# DSI_Protocol_Engine register map
Vendor: Texas Instruments
Registers are 32-bit, read-write, reset 0x0 unless marked. A register's access mark holds for its fields unless they carry their own. Offsets are as the file gives them; [hi:lo] are bit positions; {n}, {i} and the like mark numbered series; 'fields as' and 'values as' point back to an identical list.

## DSI_Protocol_Engine (part 2 of 2)
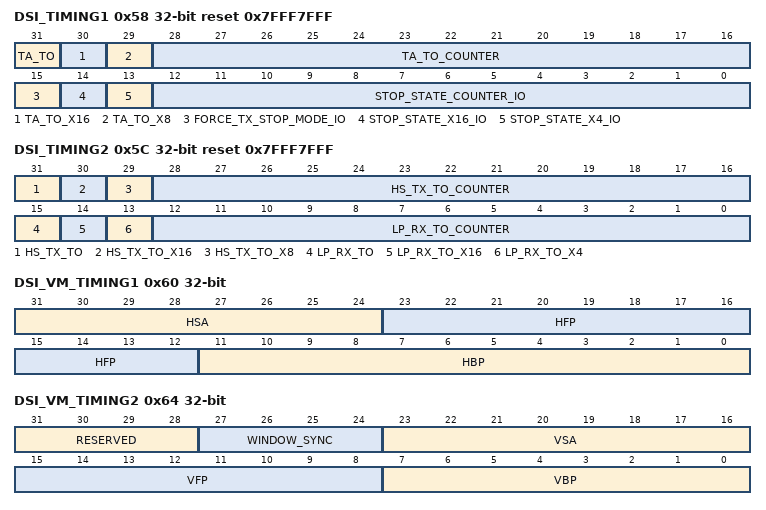
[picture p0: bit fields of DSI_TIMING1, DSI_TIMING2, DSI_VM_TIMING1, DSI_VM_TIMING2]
0x58 DSI_TIMING1 reset 0x7FFF7FFF — TIMING1 REGISTER This register controls the DSI Protocol Engine module timers. Any bit field can be modified while.IF_EN is set to 1. It is used to indicate the number of DSI_FCLK clock cycles for the timers FORCE_TX_STOP_TIMER and TA_TO_TIMER
  [31] TA_TO — Enables the turn-around timer
    0=Turn-around counter is disabled; 1=Turn-around counter is enabled (required to receive TA interrupt in case the turn-around procedure is not successful)
  [30] TA_TO_X16 — Multiplication factor for the number of DSI_FCLK clock cycles defined in TA_TO_COUNTER bit field
    0=The number of DSI_FCLK clock cycles defined in TA_TO_COUNTER is multiplied by 1x; 1=The number of DSI_FCLK clock cycles defined in TA_TO_COUNTER is multiplied by 16x
  [29] TA_TO_X8 — Multiplication factor for the number of DSI_FCLK clock cycles defined in TA_TO_COUNTER bit field
    0=The number of DSI_FCLK clock cycles defined in TA_TO_COUNTER is multiplied by 1x; 1=The number of DSI_FCLK clock cycles defined in TA_TO_COUNTER is multiplied by 8x
  [28:16] TA_TO_COUNTER — Turn around counter. It indicates the number of DSI_FCLK clock cycles to wait for the change of the Direction PPI signal according to the TurnRequest signalThe value is from 0 to 8191.
  [15] FORCE_TX_STOP_MODE_IO — Control of ForceTxStopMode signal
    0=Deassertion of ForceTxStopMode. The hardware reset the bit at the end of the ForceTXStopMode assertion. The SW can reset the bit to stop the assertion of the ForceTXStopMode signal prior to the completion of the period.; 1=Assertion of ForceTxStopMode
  [14] STOP_STATE_X16_IO — Multiplication factor for the number of DSI_FCLK clock cycles defined in STOP_STATE_COUNTER_IO bit field
    0=The number of DSI_FCLK clock cycles defined in STOP_STATE _COUNTER_IO is multiplied by 1x; 1=The number of DSI_FCLK clock cycles defined in STOP_STATE _COUNTER_IO is multiplied by 16x
  [13] STOP_STATE_X4_IO — Multiplication factor for the number of DSI_FCLK clock cycles defined in STOP_STATE_COUNTER_IO bit field
    0=The number of DSI_FCLK clock cycles defined in STOP_STATE _COUNTER_IO is multiplied by 1x; 1=The number of DSI_FCLK clock cycles defined in STOP_STATE _COUNTER_IO is multiplied by 4x
  [12:0] STOP_STATE_COUNTER_IO — Stop state counter. It indicates the number of DSI_FCLK clock cycles to assert ForceTXStopMode signal. The value is from 0 to 8191.
0x5C DSI_TIMING2 reset 0x7FFF7FFF — TIMING2 REGISTER This register controls the DSI Protocol Engine module timers. Any bit field can be modified while.IF_EN is set to 1. It is used to indicate the number of TxByteClkHS clock cycles for the timers HS_TX_TIMER and LP_RX_TIMER
  [31] HS_TX_TO — Enables the HS TX timer.
    values as DSI_TIMING1.TA_TO
  [30] HS_TX_TO_X16 — Multiplication factor for the number of TxByteClkHS functional clock cycles defined in HS_TX_COUNTER bit field
    0=The number of TxByteClkHS functional clock cycles defined in HS_TX_TO_COUNTER is multiplied by 1x; 1=The number of TxByteClkHS functional clock cycles defined in HS_TX_TO_COUNTER is multiplied by 16x
  [29] HS_TX_TO_X8 — Multiplication factor for the number of TxByteClkHS functional clock cycles defined in HS_TX_COUNTER bit
    0=The number of TxByteClkHS functional clock cycles defined in HS_TX_TO_COUNTER is multiplied by 1x; 1=The number of TxByteClkHS functional clock cycles defined in HS_TX_TO_COUNTER is multiplied by 8x
  [28:16] HS_TX_TO_COUNTER — HS_TX_TIMER counter. It indicates the number of TxByteClkHS function clock cycles for the HS TX timer.The value is from 0 to 8191.
  [15] LP_RX_TO — Enables the LP RX timer.
    values as DSI_TIMING1.TA_TO
  [14] LP_RX_TO_X16 — Multiplication factor for the number of DSI_FCLK clock cycles defined in LP_RX_COUNTER bit field
    0=The number of DSI_FCLK clock cycles defined in LP_RX_TO_COUNTER is multiplied by 1x; 1=The number of DSI_FCLK clock cycles defined in LP_RX_TO_COUNTER is multiplied by 16x
  [13] LP_RX_TO_X4 — Multiplication factor for the number of DSI_FCLK clock cycles defined in LP_RX_COUNTER bit
    0=The number of DSI_FCLK clock cycles defined in LP_RX_TO_COUNTER is multiplied by 1x; 1=The number of DSI_FCLK clock cycles defined in LP_RX_TO_COUNTER is multiplied by 4x
  [12:0] LP_RX_TO_COUNTER — LP_RX_TIMER counter. It indicates the number of DSI_FCLK clock cycles for the LP RX timer.The value is from 0 to 8191.
0x60 DSI_VM_TIMING1 — VIDEO MODE TIMING REGISTER This register defines the video mode timing.
  [31:24] HSA — Defines the horizontal Sync active period used in video mode in number of byte clock cycles (TxByteClkHS)The supported values are from 0 to 255.
  [23:12] HFP — Defines the horizontal front porch used in video mode in number of byte clock cycles (TxByteClkHS)The supported values are from 0 to 255
  [11:0] HBP — Defines the horizontal back porch used in video mode in number of byte clock cycles (TxByteClkHS)The supported values are from 0 to 255
0x64 DSI_VM_TIMING2 — VIDEO MODE TIMING REGISTER This register defines the video mode timing.
  [31:28] RESERVED — Write 0s for future compatibility.Reads returns 0.
  [27:24] WINDOW_SYNC — Number of TxByteClkHS clock cycles for the synchronization window. An interrupt for synchronization lost is generated when the received synchronization on video port is not inside the window. The DSI protocol engine does not change its own timings if the synch is inside the window. The valid values are from 0 to 15.
  [23:16] VSA — Defines the vertical Sync active period used in video mode in number of lines.The supported values are from 0 to 255 It is used to generate the short packet for End of Vertical synchronization.
  [15:8] VFP — Defines the vertical front porch used in video mode in number of lines.The supported values are from 0 to 255
  [7:0] VBP — Defines the vertical back porch used in video mode in number of lines.The supported values are from 0 to 255
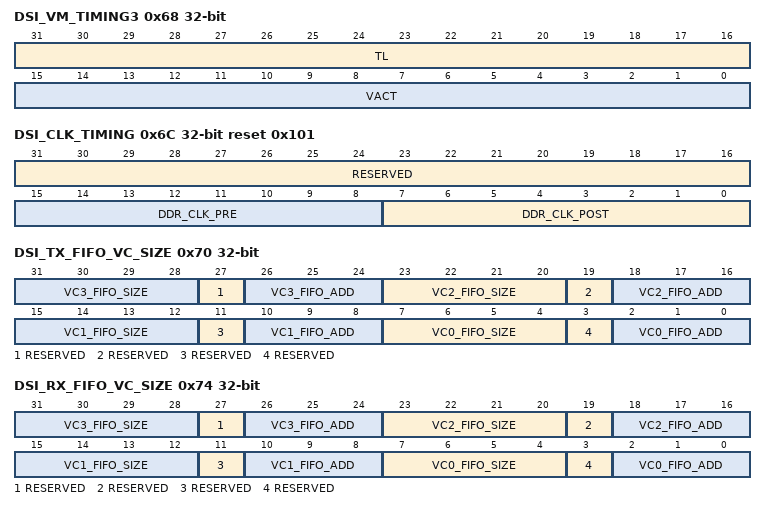
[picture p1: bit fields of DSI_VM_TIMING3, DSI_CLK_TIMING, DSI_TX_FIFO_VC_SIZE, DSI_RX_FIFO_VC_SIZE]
0x68 DSI_VM_TIMING3 — VIDEO MODE TIMING REGISTER This register defines the video mode timing.
  [31:16] TL — Defines the number of length of the line in video mode in number of byte clock cycles (TxByteClkHS)The supported values are from 0 to 8192. The values from 8193 to 65535 are not supported.
  [15:0] VACT — Defines the number of active lines used in video mode.The supported values are from 0 to 65535
0x6C DSI_CLK_TIMING reset 0x101 — CLOCK TIMING REGISTER This register controls the DSI Protocol Engine module timers. This register should not be modified while.IF_EN is set to 1.
  [31:16] RESERVED — Write 0s for future compatibility.Reads returns 0.
  [15:8] DDR_CLK_PRE — Indicates the number of TxByteClkHS cycles between the start of the DDR clock and the assertion of the data request signal. The values from 1 to 255 are valid. The value 0 is reserved. The value is not used ifDSI_CLK_CTRL[13] DDR_CLK_ALWAYS_ON is set to 1 since the DDR clock is always present.
  [7:0] DDR_CLK_POST — Indicates the number of TxByteClkHS cycles after the deassertion of the data request signal and the stop of the DDR clock. The values from 1 to 255 are valid. The value 0 is reserved. The value is not used ifDSI_CLK_CTRL[13] DDR_CLK_ALWAYS_ON is set to 1 since the DDR clock is always present.
0x70 DSI_TX_FIFO_VC_SIZE — Defines the corresponding memory entries allocated for each VC. The VC must be disabled to allocate/un-allocate some entries in the TX FIFO.
  [8n+7:8n+4] VC{n}_FIFO_SIZE (n=0..3) — Size of the FIFO allocated for VC {n}. For a complete description, refer to.
  [27] RESERVED — Write 0s for future compatibility.Reads returns 0.
  [26:24] VC3_FIFO_ADD — Address of the space allocated in the FIFO for VC 3. For a complete description, refer to.
  [19] RESERVED — Write 0s for future compatibility.Reads returns 0.
  [18:16] VC2_FIFO_ADD — Address of the space allocated in the FIFO for VC 2. For a complete description, refer to.
  [11] RESERVED — Write 0s for future compatibility.Reads returns 0.
  [10:8] VC1_FIFO_ADD — Address of the space allocated in the FIFO for VC 1.For a complete description, refer to.
  [3] RESERVED — Write 0s for future compatibility.Reads returns 0.
  [2:0] VC0_FIFO_ADD — Address of the space allocated in the FIFO for VC 0. For a complete description, refer to.
0x74 DSI_RX_FIFO_VC_SIZE — Defines the corresponding memory entries allocated for each VC and the addresses. The VC must be disabled to allocate/un-allocate some entries in the RX FIFO.
  [8n+7:8n+4] VC{n}_FIFO_SIZE (n=0..3) — Size of the FIFO allocated for VC {n}. For a complete description, refer to.
  [27] RESERVED — Write 0s for future compatibility.Reads returns 0.
  [26:24] VC3_FIFO_ADD — Address of the space allocated in the FIFO for VC 3.For a complete description, refer to.
  [19] RESERVED — Write 0s for future compatibility.Reads returns 0.
  [18:16] VC2_FIFO_ADD — Address of the space allocated in the FIFO for VC 2. For a complete description, refer to.
  [11] RESERVED — Write 0s for future compatibility.Reads returns 0.
  [10:8] VC1_FIFO_ADD — Address of the space allocated in the FIFO for VC 1. For a complete description, refer to.
  [3] RESERVED — Write 0s for future compatibility.Reads returns 0.
  [2:0] VC0_FIFO_ADD — Address of the space allocated in the FIFO for VC 0. For a complete description, refer to.
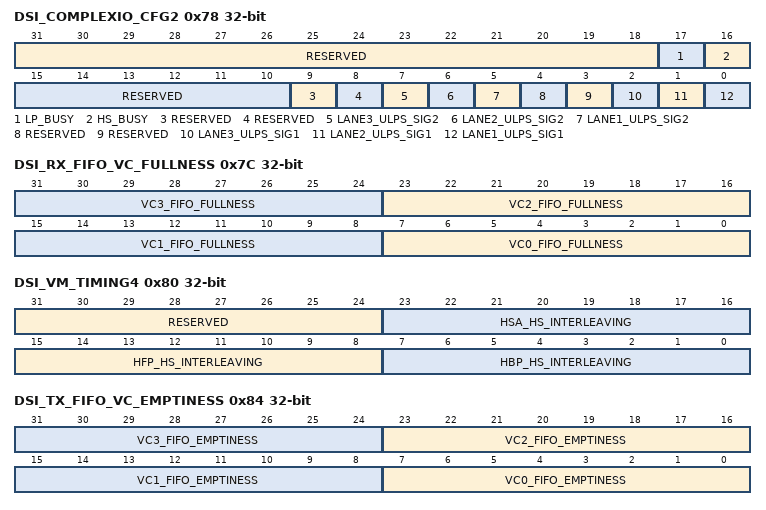
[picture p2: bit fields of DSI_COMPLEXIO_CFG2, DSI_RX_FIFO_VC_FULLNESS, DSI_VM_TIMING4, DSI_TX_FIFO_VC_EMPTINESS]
0x78 DSI_COMPLEXIO_CFG2 access per field — COMPLEXIO CONFIGURATION REGISTER for the complex I/O This register contains the lane configuration for the ULPS for each lane.
  [31:18] RESERVED rw — Write 0s for future compatibility.Reads returns 0.
  [17] LP_BUSY ro — Indicates when there are still pending operations for VCs configured for LP mode. Forced to 1 when at least one VC is enabled and configured for LP mode.
    0=LP_BUSY_0_r (LP logic is idle); 1=LP_BUSY_1_r (LP logic is active)
  [16] HS_BUSY ro — Indicates when there are still pending operations for VCs configured for HS mode. Forced to 1 when at least one VC is enabled and configured for HS mode
    0=HS_BUSY_0_r (HS logic is idle); 1=HS_BUSY_1_r (HS logic is active)
  [15:10] RESERVED rw — Write 0s for future compatibility.Reads returns 0.
  [9] RESERVED rw — Write 0s for future compatibility.Reads returns 0.
  [8] RESERVED rw — Write 0s for future compatibility.Reads returns 0.
  [7] LANE3_ULPS_SIG2 rw — Enables the ULPS for the lane #3. The HW should change the state of the lane to ULPS only when it is in stop state and there is no data pending inside the DSI protocol engine and the DSI protocol engine has control of the bus (BTA has not been sent).The state of the signal TxRequestEsc is change if lane #3 is a data lane.The state of the signal TxUlpsClk is change if lane #3 is a clock lane.There will be a latency depending on the frequency of TxClkExc. This bit should be read back to confirm a write has been effective.
    0=READ: Inactive state effectiveWRITE: Request to change to inactive state; 1=READ: Active state effectiveWRITE: Change request to active. If the lane is a data lane, TxRequestEsc is asserted and synchronously TxUlpsEsc is asserted for one period of TxClkEsc.
  [6] LANE2_ULPS_SIG2 rw — Enables the ULPS for the lane #2. The HW should change the state of the lane to ULPS only when it is in stop state and there is no data pending inside the DSI protocol engine and the DSI protocol engine has control of the bus (BTA has not been sent).The state of the signal TxRequestEsc is change if lane #2 is a data lane.The state of the signal TxUlpsClk is change if lane #2 is a clock lane.There will be a latency depending on the frequency of TxClkExc. This bit should be read back to confirm a write has been effective.
    0=READ: Inactive state effective WRITE: Request to change to inactive state; 1=READ: ACTIVE state effective WRITE: Change request to active. If the lane is a data lane, TxRequestEsc is asserted and synchronously TxUlpsEsc is asserted for one period of TxClkEsc.
  [5] LANE1_ULPS_SIG2 rw — Enables the ULPS for the lane #1. The HW should change the state of the lane to ULPS only when it is in stop state and there is no data pending inside the DSI protocol engine and the DSI protocol engine has control of the bus (BTA has not been sent).The state of the signal TxRequestEsc is change if lane #1 is a data lane.The state of the signal TxUlpsClk is change if lane #1 is a clock lane. There will be a latency depending on the frequency of TxClkExc. This bit should be read back to confirm a write has been effective.
    values as LANE2_ULPS_SIG2
  [4] RESERVED rw — Write 0s for future compatibility.Reads returns 0.
  [3] RESERVED rw — Write 0s for future compatibility.Reads returns 0.
  [2] LANE3_ULPS_SIG1 rw — Enables the ULPS for the lane #3. The HW should change the state of the lane to ULPS only when it is in stop state and there is no data pending inside the DSI protocol engine and the DSI protocol engine has control of the bus (BTA has not been sent).The state of the signal TxULPSExit is changed if lane #3 is a clock lane. There will be a latency depending on the frequency of TxClkExc. This bit should be read back to confirm a write has been effective.
    values as LANE2_ULPS_SIG2
  [1] LANE2_ULPS_SIG1 rw — Enables the ULPS for the lane #2. The HW must change the state of the lane to ULPS only when it is in stop state and there is no data pending inside the DSI protocol engine and the DSI protocol engine has control of the bus (BTA has not been sent).The state of the signal TxULPSExit is changed if lane #3 is a clock lane. There will be a latency depending on the frequency of TxClkExc. This bit should be read back to confirm a write has been effective.
    values as LANE2_ULPS_SIG2
  [0] LANE1_ULPS_SIG1 rw — Enables the ULPS for the lane #1. The HW must change the state of the lane to ULPS only when it is in stop state and there is no data pending inside the DSI protocol engine and the DSI protocol engine has control of the bus (BTA has not been sent).The state of the signal TxULPSExit is changed if lane #3 is a clock lane.There will be a latency depending on the frequency of TxClkExc. This bit should be read back to confirm a write has been effective.
    values as LANE2_ULPS_SIG2
0x7C DSI_RX_FIFO_VC_FULLNESS ro — Defines the fullness of each space allocated for each VC.
  [8n+7:8n] VC{n}_FIFO_FULLNESS (n=0..3) — Fullness of the FIFO allocated for VC {n}.The valid values are from 0 to 127 corresponding to 1x33-bit,...up to 128x33-bit.
0x80 DSI_VM_TIMING4 — VIDEO MODE TIMING REGISTER This register defines the video mode timing.
  [31:24] RESERVED — Write 0s for future compatibility.Reads returns 0.
  [23:16] HSA_HS_INTERLEAVING — Defines the number of TxByteClkHS cycles that can be used for interleaving high-speed command mode packet into Video Mode stream during HSA blanking period.The supported values are from 0 to 255.
  [15:8] HFP_HS_INTERLEAVING — Defines the number of TxByteClkHS cycles that can be used for interleaving high-speed command mode packet into Video Mode stream during HFP blanking period.The supported values are from 0 to 255
  [7:0] HBP_HS_INTERLEAVING — Defines the number of TxByteClkHS cycles that can be used for interleaving high-speed command mode packet into Video Mode stream during HBP blanking period.The supported values are from 0 to 255
0x84 DSI_TX_FIFO_VC_EMPTINESS ro — Defines the emptiness of each space allocated for each VC.
  [8n+7:8n] VC{n}_FIFO_EMPTINESS (n=0..3) — Emptiness of the FIFO allocated for VC {n}.The valid values are from 0 to 127 corresponding to 1x33-bit,...up to128x33-bit.
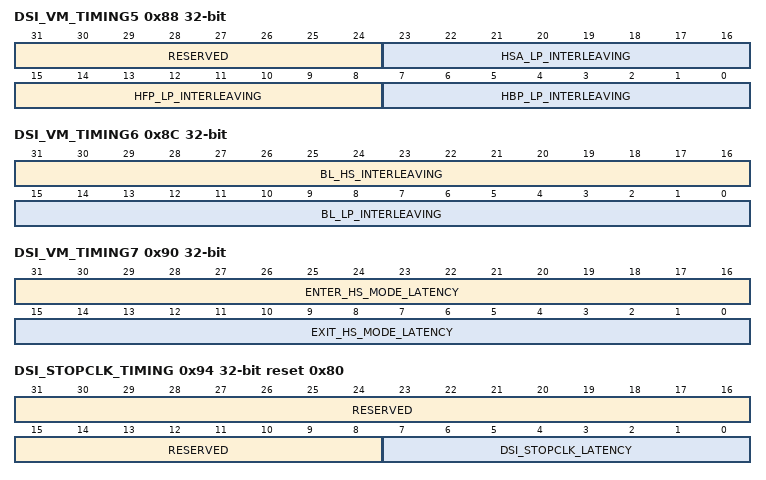
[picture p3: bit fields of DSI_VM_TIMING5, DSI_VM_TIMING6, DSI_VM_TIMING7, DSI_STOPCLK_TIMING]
0x88 DSI_VM_TIMING5 — VIDEO MODE TIMING REGISTER This register defines the video mode timing.
  [31:24] RESERVED — Write 0s for future compatibility.Reads returns 0.
  [23:16] HSA_LP_INTERLEAVING — Defines the number of bytes for Low Power command mode packets that can be sent on PPI link during HSA blanking period.The supported values are from 0 to 255.
  [15:8] HFP_LP_INTERLEAVING — Defines the number of bytes for Low Power command mode packets that can be sent on PPI link during HFP blanking period.The supported values are from 0 to 255
  [7:0] HBP_LP_INTERLEAVING — Defines the number of bytes for Low Power command mode packets that can be sent on PPI link during HBP blanking period.The supported values are from 0 to 255
0x8C DSI_VM_TIMING6 — VIDEO MODE TIMING REGISTER This register defines the video mode timing.
  [31:16] BL_HS_INTERLEAVING — Defines the number of TxByteClkHS clock cycles that can be used for interleaving high-speed command mode packet into Video Mode stream during blanking periods during VSA, VBP, VFP periods inside one video frame on PPI link.The supported values are from 0 to 65535.
  [15:0] BL_LP_INTERLEAVING — Defines the maximum number of bytes for Low Power command mode packets that can be sent on PPI link during blanking periods during VSA, VBP or VFP periods inside one video frame on PPI link.The supported values are from 0 to 65535
0x90 DSI_VM_TIMING7 — Defines the maximum number of bytes of Low Power command mode packets that can be sent on PPI link during blanking periods during VSA, VBP or VFP periods inside one video frame on PPI link. The supported values are from 0 to 65535
  [31:16] ENTER_HS_MODE_LATENCY — Defines the number of TxByteClkHS clock cycles necessary for entering to HS mode. It corresponds to the delay in number of HS clock cycles from assertion of TxRequestHS signal to 1 until assertion of TxReadyHS signal to 1.The supported values are from 0 to 65535 .
  [15:0] EXIT_HS_MODE_LATENCY — Defines the number of TxByteClkHS clock cycles necessary for exiting from HS mode. It corresponds to the maximum delay in number of TxByteClkHS clock cycles from deassertion of TxRequestHS signal until PPI link is in LP-11 state from which a new entrance to HS mode can be initiated which does not take more than ENTER_HS_MODE_LATENCY clock cycles.The supported values are from 0 to 65535
0x94 DSI_STOPCLK_TIMING access per field reset 0x80 — Number of functional clock cycles to wait for TxByteClock to stop/start after change in DSIStopClk signal
  [31:8] RESERVED ro — Write 0s for future compatibility. Reads returns 0.
  [7:0] DSI_STOPCLK_LATENCY rw — Clock gating latency from DSI Protocol engine to TxByteClkHS
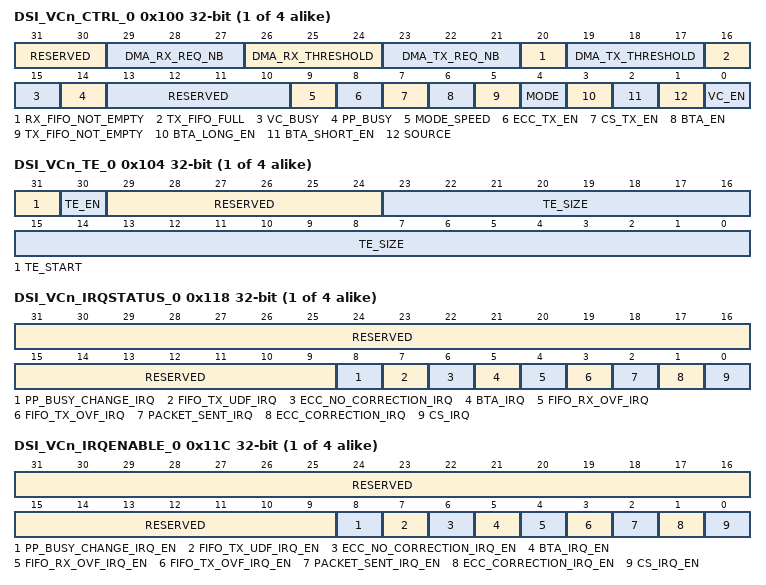
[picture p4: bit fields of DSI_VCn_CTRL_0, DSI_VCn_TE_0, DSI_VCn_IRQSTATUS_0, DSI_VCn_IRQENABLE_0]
{0x100+0x20*i} DSI_VCn_CTRL_{i} access per field (i=0..3) — CONTROL REGISTER - Virtual channel This register controls the VC.
  [31:30] RESERVED rw — Write 0s for future compatibility.Reads returns 0.
  [29:27] DMA_RX_REQ_NB rw — Selection of the use of the DMA request (associated to the RX FIFO)
    {v}=DSI_DMA_REQ{v} is selected (v=0..3); 4=No DMA req selected
  [26:24] DMA_RX_THRESHOLD rw — Defines the threshold value for the DMA request (associated to the RX FIFO)
    0=1x 32 bits; 1=2 x 32 bits; 2=4 x 32 bits; 3=8 x 32 bits; 4=16 x 32 bits; 5=32 x 32 bits
  [23:21] DMA_TX_REQ_NB rw — Selection of the use of the DMA request (associated to the TX FIFO)
    values as DMA_RX_REQ_NB
  [20] RX_FIFO_NOT_EMPTY ro — FIFO status in command mode. Otherwise, this bit can be ignored.
    0=The RX FIFO is empty (the FIFO does not contain any data for the VC); 1=The RX FIFO is not empty (the FIFO contains at least one byte for the VC)
  [19:17] DMA_TX_THRESHOLD rw — Defines the threshold value for the DMA request (associated to the TX FIFO)
    values as DMA_RX_THRESHOLD
  [16] TX_FIFO_FULL ro — FIFO status in command mode. Otherwise, this bit can be ignored.
    0=The TX FIFO is not full (the FIFO can accept at least one more 32-bit value); 1=The TX FIFO is full
  [15] VC_BUSY ro — Indicates if previously scheduled activities (packets, BTA) are still being processed. Forced to 1 by hardware if VC is enabled. Software should check this bit is 0 before changing channel configuration.
    0=No pending operations for this VC; 1=Pending operations for this VC
  [14] PP_BUSY ro — Line buffer busy status.
    0=Software is permitted to write a new header for VP command mode traffic; 1=Software is NOT permitted to write a new header for VP command mode traffic
  [13:10] RESERVED rw — Write 0s for future compatibility.Reads returns 0.
  [9] MODE_SPEED rw — Selection of the mode. This bit is ignored by hardware when video mode is selected.
    0=Low-power mode (CMOS) is used to send short and long packets to the peripheral; 1=High speed mode (SLVS) is used to send short and long packets to the peripheral
  [8] ECC_TX_EN rw — Enables the ECC generation for the transmit header (short and long packets).
    0=Disabled; 1=Enabled
  [7] CS_TX_EN rw — Enables the checksum generation for the transmit payload (long packet only).
    0=Disabled. The value 0x00 is used.; 1=Enabled. The Check-sum value is calculated by HW.
  [6] BTA_EN rw — Send the bus turn around to the peripheral. It can be used when the automatic mode is enabled (BTA_SHORT_EN=1 or/and BTA_LONG_EN=1). In that case only one BTA is sent to the peripheral. The manual mode allows users to define for which packets, the turn around is required for example getting acknowledge from the peripheral.
    0=READS: BTA generation is completed. It is reset by HW when it is completed.WRITES: Cancellation of the BTA generation (not guarantee since it could already on going, must not be used).; 1=READS: BTA generation has been requested by user (it could be on going but not completed). WRITES: Request for BTA generation.
  [5] TX_FIFO_NOT_EMPTY ro — FIFO status
    0=The TX FIFO is empty (the FIFO does not contain any data for the VC); 1=The TX FIFO is not empty (the FIFO contains at least one byte for the VC)
  [4] MODE rw — Selection of the mode
    0=Command mode; 1=Video mode
  [3] BTA_LONG_EN rw — Enables the automatic bus turn-around after completion of each long packet transmission.
    0=Disabled; 1=Enabled
  [2] BTA_SHORT_EN rw — Enables the automatic bus turn-around after completion of each short packet transmission.
    0=Disabled; 1=Enabled
  [1] SOURCE rw — Selection of the source between L4 interconnect slave port and video port. This bit is ignored by hardware when video mode is selected.
    0=All the data are provided by the L4 interconnect slave port. Any transfer on the video port is ignored for this VC.; 1=If MODE=VIDEO_MODE. any data received on the video port (pixels and enabled synchronization events using[17] VP_HSYNC_START, [18] VP_HSYNC_END, [15] VP_VSYNC_START, [16] VP_VSYNC_END,) are sent on the VC (only one VC can be associated with the video port, the software must ensure that no more than one VC is enabled with the video port as the main source for data). If MODE=COMMAND_MODE, the VP_STALL signal is used by the protocol engine to indicate when new data are required. The synchronization signals are not generated by the display controller. Regardless of the MODE, no data can be provided on the L4 interconnect slave port.
  [0] VC_EN rw — Enables the VC.
    0=Disabled. The VC must be disabled for any register change in the DSI_VCn_XXX registers the corresponding VC ID.; 1=Enabled. No change is allowed to the VC registers (except for setting the bit fields/registers:[6] BTA_EN, [15:0] TE_SIZE, [31] TE_START, DSI_VCn_LONG_XXX, DSI_VCn_SHORT_XXX, DSI_VCn_IRQXXX registers).
{0x104+0x20*i} DSI_VCn_TE_{i} (i=0..3) — CONTROL REGISTER - Virtual channel This register controls the tearing effect logic. It defines the size of the transfer when TE occurs and enables the automatic TE mode.
  [31] TE_START — Manual control of the start of the transfer. Users can use the TE interrupt to determine that the TE trigger has been received before setting the TE_START bit field. It is not mandatory to use the TE interrupt.
    0=Indicates the end of the transfer. The bit can be used to cancel the transfer if not already started. The FIFO must be flushed by software to ensure it contains no remaining data.; 1=Starts the transfer of the data. The size is defined in TE_SIZE. The bit field is set until the transfer completes. It is reset by hardware when the transfer completes.
  [30] TE_EN — Tearing effect control
    0=Disables the automatic transfer of the data using the TE trigger as a synchronization event. The interruption is used to know when the TE trigger is received. The hardware resets the bit field when the transfer completes(TE_SIZE=0).; 1=Enables the automatic transfer of the data using the TE trigger as a synchronization event
  [29:24] RESERVED — Write 0s for future compatibility.Reads returns 0.
  [23:0] TE_SIZE — Defines the number of bytes (payload data excluding the check-sum) to be sent. Users must perform the write into theDSI_VCn_LONG_PACKET_HEADER register before sending data from the DSI_VCn_LONG_PACKET_PAYLOAD register. The register value is decremented for every byte of the DSI link that is sent. At the end of the transfer (TE_SIZE = 0), the TE_EN bit field is reset by hardware. The DMA_request is asserted when the trigger is received in order to receive data in the TX FIFO. It must not be used until all data (TE_SIZE) have been received in the FIFO.
{0x108+0x20*i} DSI_VCn_LONG_PACKET_HEADER_{i} wo (i=0..3) — LONG PACKET HEADER INFORMATION–virtual channel. This register sets the 32-bit DATA_ID + Word count + ECC. The ECC is computed if ECC_TX_EN is set to 1.
  [31:0] HEADER — Packet header information: DATA ID + DATA FIELD +ECC
{0x10C+0x20*i} DSI_VCn_LONG_PACKET_PAYLOAD_{i} wo (i=0..3) — LONG PACKET PAYLOAD INFORMATION–virtual channel. This register sets the payload information (excluding Check-sum). Hardware must capture the word count in the packet header (in register) to determine the last valid data (the VC ID can be different from VC). Byte1 is bit[7:0]; Byte2 is bit[15:8]; Byte3 is bit[23:16]; Byte4 is bit[31:24]; and Byten is sent before Byten+1 (least-significant byte first and least significant bit first).
  [31:0] PAYLOAD — Packet payload information (excluding check-sum)
{0x110+0x20*i} DSI_VCn_SHORT_PACKET_HEADER_{i} (i=0..3) — SHORT PACKET HEADER INFORMATION -Virtual channel This register sets the 24-bit DATA_ID + Short packet data field + ECC (the VC ID can be different than VC) DATA_ID is located at bit[7:0] short packet data field is located at bit[23:8] ECC is located at bit[31:24] (least-significant byte first and least significant bit first)
  [31:0] HEADER — WRITES: Packet header information: DATA ID + DATA FIELD +ECC written into the TX FIFOREADS: 32-bit values read from the RX FIFO
{0x118+0x20*i} DSI_VCn_IRQSTATUS_{i} (i=0..3) — INTERRUPT STATUS REGISTER - Virtual channel This register regroups all the events related to the VC.
  [31:9] RESERVED — Write 0s for future compatibility.Reads returns 0.
  [8] PP_BUSY_CHANGE_IRQ — Video port ping-pong buffer busy status.
    0=READS: Event is false.WRITES: Status bit unchanged; 1=READS: Event is true (pending).WRITES: Status bit is reset
  [7] FIFO_TX_UDF_IRQ — FIFO underflow status. The FIFO used on the slave port for buffering the data received on the OCP slave port for the VC has underflowed which means that the data for the current packet have not been received in time since the transfer of the packet are already started (transfer started since the packet size is bigger than space allocated in the FIFO).
    values as PP_BUSY_CHANGE_IRQ
  [6] ECC_NO_CORRECTION_IRQ — ECC error status (short and long packets). No correction of the header because of more than 1-bit error.
    values as PP_BUSY_CHANGE_IRQ
  [5] BTA_IRQ — Virtual channel - BTA status.
    values as PP_BUSY_CHANGE_IRQ
  [4] FIFO_RX_OVF_IRQ — FIFO overflow error status. The FIFO used on the slave port for buffering the data received on the DSI link for the VC has overflowed.
    values as PP_BUSY_CHANGE_IRQ
  [3] FIFO_TX_OVF_IRQ — FIFO overflow error status. The FIFO used on the slave port for buffering the data received on the OCP slave port for the VC has overflowed.
    0=READS: Event is false. WRITES: Status bit unchanged.; 1=READS: Event is true (pending).WRITES: Status bit is reset
  [2] PACKET_SENT_IRQ — Indicates that a packet has been sent. It is used when BTA manual mode is used.
    values as FIFO_TX_OVF_IRQ
  [1] ECC_CORRECTION_IRQ — Virtual channel - ECC has been used to do the correction of the only 1-bit error status (short and long packet only).
    0=READS: Event is false. WRITES: Status bit unchanged.; 1=READS: Event is true (pending). WRITES: Status bit is reset.
  [0] CS_IRQ — Virtual channel - Check-Sum mismatch status.
    values as PP_BUSY_CHANGE_IRQ
{0x11C+0x20*i} DSI_VCn_IRQENABLE_{i} (i=0..3) — INTERRUPT ENABLE REGISTER - Virtual channel This register regroups all the events related to VC.
  [31:9] RESERVED — Write 0s for future compatibility.Reads returns 0.
  [8] PP_BUSY_CHANGE_IRQ_EN — Video port ping-pong buffer busy.
    0=Event is masked; 1=Event generates an interrupt when it occurs
  [7] FIFO_TX_UDF_IRQ_EN — FIFO underflow enable. The FIFO used on the slave port for buffering the data received on the OCP slave port for the VC has underflowed which means that the data for the current packet have not been received in time since the transfer of the packet are already started (transfer started since the packet size is bigger than space allocated in the FIFO).
    values as PP_BUSY_CHANGE_IRQ_EN
  [6] ECC_NO_CORRECTION_IRQ_EN — ECC error (short and long packets). No correction of the header because of more than 1-bit error.
    values as PP_BUSY_CHANGE_IRQ_EN
  [5] BTA_IRQ_EN — Virtual channel -Bus turn around reception
    values as PP_BUSY_CHANGE_IRQ_EN
  [4] FIFO_RX_OVF_IRQ_EN — FIFO overflow enable. The FIFO used on the slave port for buffering the data received on the DSI link for the VC has overflowed.
    values as PP_BUSY_CHANGE_IRQ_EN
  [3] FIFO_TX_OVF_IRQ_EN — FIFO overflow enable. The FIFO used on the slave port for buffering the data received on the OCP slave port for the VC has overflowed.
    values as PP_BUSY_CHANGE_IRQ_EN
  [2] PACKET_SENT_IRQ_EN — Indicates that a packet has been sent. It is used when BTA manual mode is used.
    values as PP_BUSY_CHANGE_IRQ_EN
  [1] ECC_CORRECTION_IRQ_EN — Virtual channel - ECC has been used to correct the only 1-bit error (short and long packet).
    values as PP_BUSY_CHANGE_IRQ_EN
  [0] CS_IRQ_EN — Virtual channel - Check-Sum of the payload mismatch detection
    values as PP_BUSY_CHANGE_IRQ_EN
